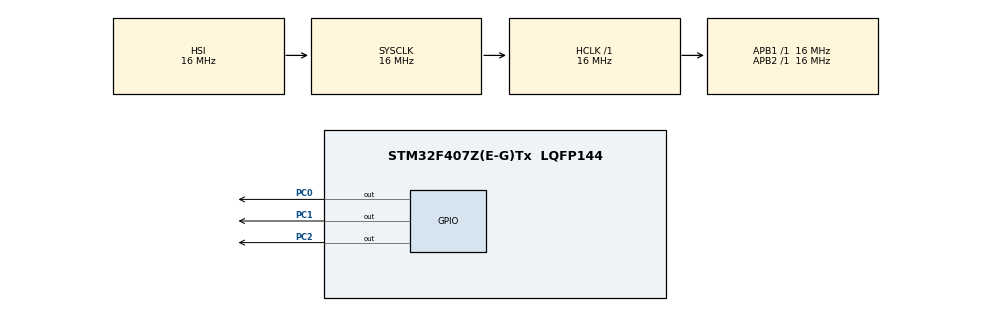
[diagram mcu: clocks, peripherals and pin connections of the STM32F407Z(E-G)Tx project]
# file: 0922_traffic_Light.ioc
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Mcu.Family=STM32F4
Mcu.Name=STM32F407Z(E-G)Tx
Mcu.Package=LQFP144
NVIC.PriorityGroup=NVIC_PRIORITYGROUP_4
NVIC.TIM1_TRG_COM_TIM11_IRQn=true\:0\:0\:false\:false\:true\:true\:true\:true
PC0.Signal=GPIO_Output
PC1.Signal=GPIO_Output
PC2.Signal=GPIO_Output
ProjectManager.HeapSize=0x200
ProjectManager.StackSize=0x400
ProjectManager.TargetToolchain=CMake
RCC.AHBFreq_Value=16000000
RCC.APB1Freq_Value=16000000
RCC.APB2Freq_Value=16000000
RCC.CortexFreq_Value=16000000
RCC.HSE_VALUE=25000000
RCC.HSI_VALUE=16000000
RCC.LSE_VALUE=32768
RCC.SYSCLKFreq_VALUE=16000000
RCC.VCOOutputFreq_Value=192000000
VP_TIM1_VS_ClockSourceINT.Mode=Internal
board=custom

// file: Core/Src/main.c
/* USER CODE BEGIN Header */
/**
  ******************************************************************************
  * @file           : main.c
  * @brief          : Main program body
  ******************************************************************************
  * @attention
  *
  * Copyright (c) 2025 STMicroelectronics.
  * All rights reserved.
  *
  * This software is licensed under terms that can be found in the LICENSE file
  * in the root directory of this software component.
  * If no LICENSE file comes with this software, it is provided AS-IS.
  *
  ******************************************************************************
  */
/* USER CODE END Header */
#include "main.h"
#include "tim.h"
#include "gpio.h"
#include <stdbool.h>

	uint8_t T = 0;
uint8_t i = 0;

void SystemClock_Config(void);

int main(void)
{

  /* MCU Configuration--------------------------------------------------------*/

  /* Reset of all peripherals, Initializes the Flash interface and the Systick. */
  HAL_Init();

  /* Configure the system clock */
  SystemClock_Config();

  /* Initialize all configured peripherals */
  MX_GPIO_Init();
  MX_TIM1_Init();

  /* Infinite loop */
  /* USER CODE BEGIN WHILE */
//bool istimerruning =true;
  while (1)
  {

    i=T%25;
    if (i>=1 && i<= 10)
    HAL_GPIO_WritePin(GPIOC, GPIO_PIN_0, GPIO_PIN_SET);

    HAL_GPIO_WritePin(GPIOC, GPIO_PIN_0, GPIO_PIN_RESET);

    if (i>= 11 &&i <= 17)
      HAL_GPIO_WritePin(GPIOC, GPIO_PIN_2, GPIO_PIN_SET);
    if (i== 18)
      HAL_GPIO_WritePin(GPIOC, GPIO_PIN_2, GPIO_PIN_RESET);
    if (i== 19)
      HAL_GPIO_WritePin(GPIOC, GPIO_PIN_2, GPIO_PIN_SET);

    if (i==20)
      HAL_GPIO_WritePin(GPIOC, GPIO_PIN_2, GPIO_PIN_RESET);

    HAL_GPIO_WritePin(GPIOC, GPIO_PIN_2, GPIO_PIN_RESET);
    HAL_GPIO_WritePin(GPIOC, GPIO_PIN_2, GPIO_PIN_RESET);
    if (i>=21&&i<=25)
      HAL_GPIO_WritePin(GPIOC, GPIO_PIN_2, GPIO_PIN_SET);

    HAL_GPIO_WritePin(GPIOC, GPIO_PIN_2, GPIO_PIN_RESET);

    /* USER CODE END WHILE */

  }
}

void SystemClock_Config(void)
{
  RCC_OscInitTypeDef RCC_OscInitStruct = {0};
  RCC_ClkInitTypeDef RCC_ClkInitStruct = {0};

  /** Configure the main internal regulator output voltage
  */
  __HAL_RCC_PWR_CLK_ENABLE();
  __HAL_PWR_VOLTAGESCALING_CONFIG(PWR_REGULATOR_VOLTAGE_SCALE1);

  /** Initializes the RCC Oscillators according to the specified parameters
  * in the RCC_OscInitTypeDef structure.
  */
  RCC_OscInitStruct.OscillatorType = RCC_OSCILLATORTYPE_HSI;
  RCC_OscInitStruct.HSIState = RCC_HSI_ON;
  RCC_OscInitStruct.HSICalibrationValue = RCC_HSICALIBRATION_DEFAULT;
  RCC_OscInitStruct.PLL.PLLState = RCC_PLL_NONE;
  if (HAL_RCC_OscConfig(&RCC_OscInitStruct) != HAL_OK)
  {
    Error_Handler();
  }

  /** Initializes the CPU, AHB and APB buses clocks
  */
  RCC_ClkInitStruct.ClockType = RCC_CLOCKTYPE_HCLK|RCC_CLOCKTYPE_SYSCLK
                              |RCC_CLOCKTYPE_PCLK1|RCC_CLOCKTYPE_PCLK2;
  RCC_ClkInitStruct.SYSCLKSource = RCC_SYSCLKSOURCE_HSI;
  RCC_ClkInitStruct.AHBCLKDivider = RCC_SYSCLK_DIV1;
  RCC_ClkInitStruct.APB1CLKDivider = RCC_HCLK_DIV1;
  RCC_ClkInitStruct.APB2CLKDivider = RCC_HCLK_DIV1;

  if (HAL_RCC_ClockConfig(&RCC_ClkInitStruct, FLASH_LATENCY_0) != HAL_OK)
  {
    Error_Handler();
  }
}

/* USER CODE BEGIN 4 */
void HAL_TIM_PeriodElapsedCallback(TIM_HandleTypeDef *htim)
{
	if(htim==&htim1)
	{
		if(T<UINT8_MAX)
		{
			T++;
		}
		else
		{
			T=0;
		}

	}
}
/* USER CODE END 4 */

void Error_Handler(void)
{
  __disable_irq();
  while (1)
  {
  }
}
